AUTOSAR XML (schema 00051)
package /ComponentTypes
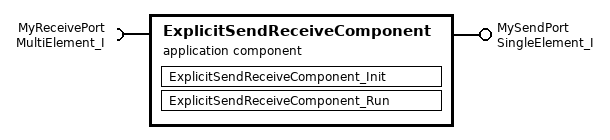
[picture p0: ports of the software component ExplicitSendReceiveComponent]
  application sw component type ExplicitSendReceiveComponent
    require port MyReceivePort: required-com-specs=[{data-element=Value1, init-value=65535}, {data-element=Value2, init-value=255}], required-interface=MultiElement_I
    provide port MySendPort: nonqueued-sender-com-spec{data-element=Value, init-value=65535}, provided-interface=SingleElement_I
    behavior ExplicitSendReceiveComponent_InternalBehavior
      runnable ExplicitSendReceiveComponent_Init
      runnable ExplicitSendReceiveComponent_Run
        data-receive-point-by-arguments:
          access REC_MyReceivePort_Value2: accessed-variable=MyReceivePort.Value2
        data-receive-point-by-values:
          access REC_MyReceivePort_Value1: accessed-variable=MyReceivePort.Value1
        data-send-points:
          access SEND_MySendPort_Value: accessed-variable=MySendPort.Value
  swc implementation ExplicitSendReceiveComponent_Implementation: behavior=ExplicitSendReceiveComponent_InternalBehavior
